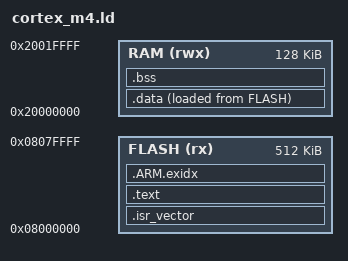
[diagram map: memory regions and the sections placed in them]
/* Memory layout of a typical small Cortex-M4 chip:
 * 512 KB flash starting at 0x08000000, 128 KB RAM at 0x20000000 */
MEMORY
{
  FLASH (rx)  : ORIGIN = 0x08000000, LENGTH = 512K
  RAM   (rwx) : ORIGIN = 0x20000000, LENGTH = 128K
}

_estack = ORIGIN(RAM) + LENGTH(RAM);
ENTRY(Reset_Handler)

SECTIONS
{
  .isr_vector : { KEEP(*(.isr_vector)) } > FLASH
  .text   : { *(.text*) *(.rodata*) . = ALIGN(4); } > FLASH
  .ARM.exidx : { *(.ARM.exidx*) } > FLASH
  _sidata = LOADADDR(.data);
  .data   : { _sdata = .; *(.data*) . = ALIGN(4); _edata = .; } > RAM AT > FLASH
  .bss    : { _sbss = .; *(.bss*) *(COMMON) . = ALIGN(4); _ebss = .; } > RAM
  end = .; _end = .;
}
